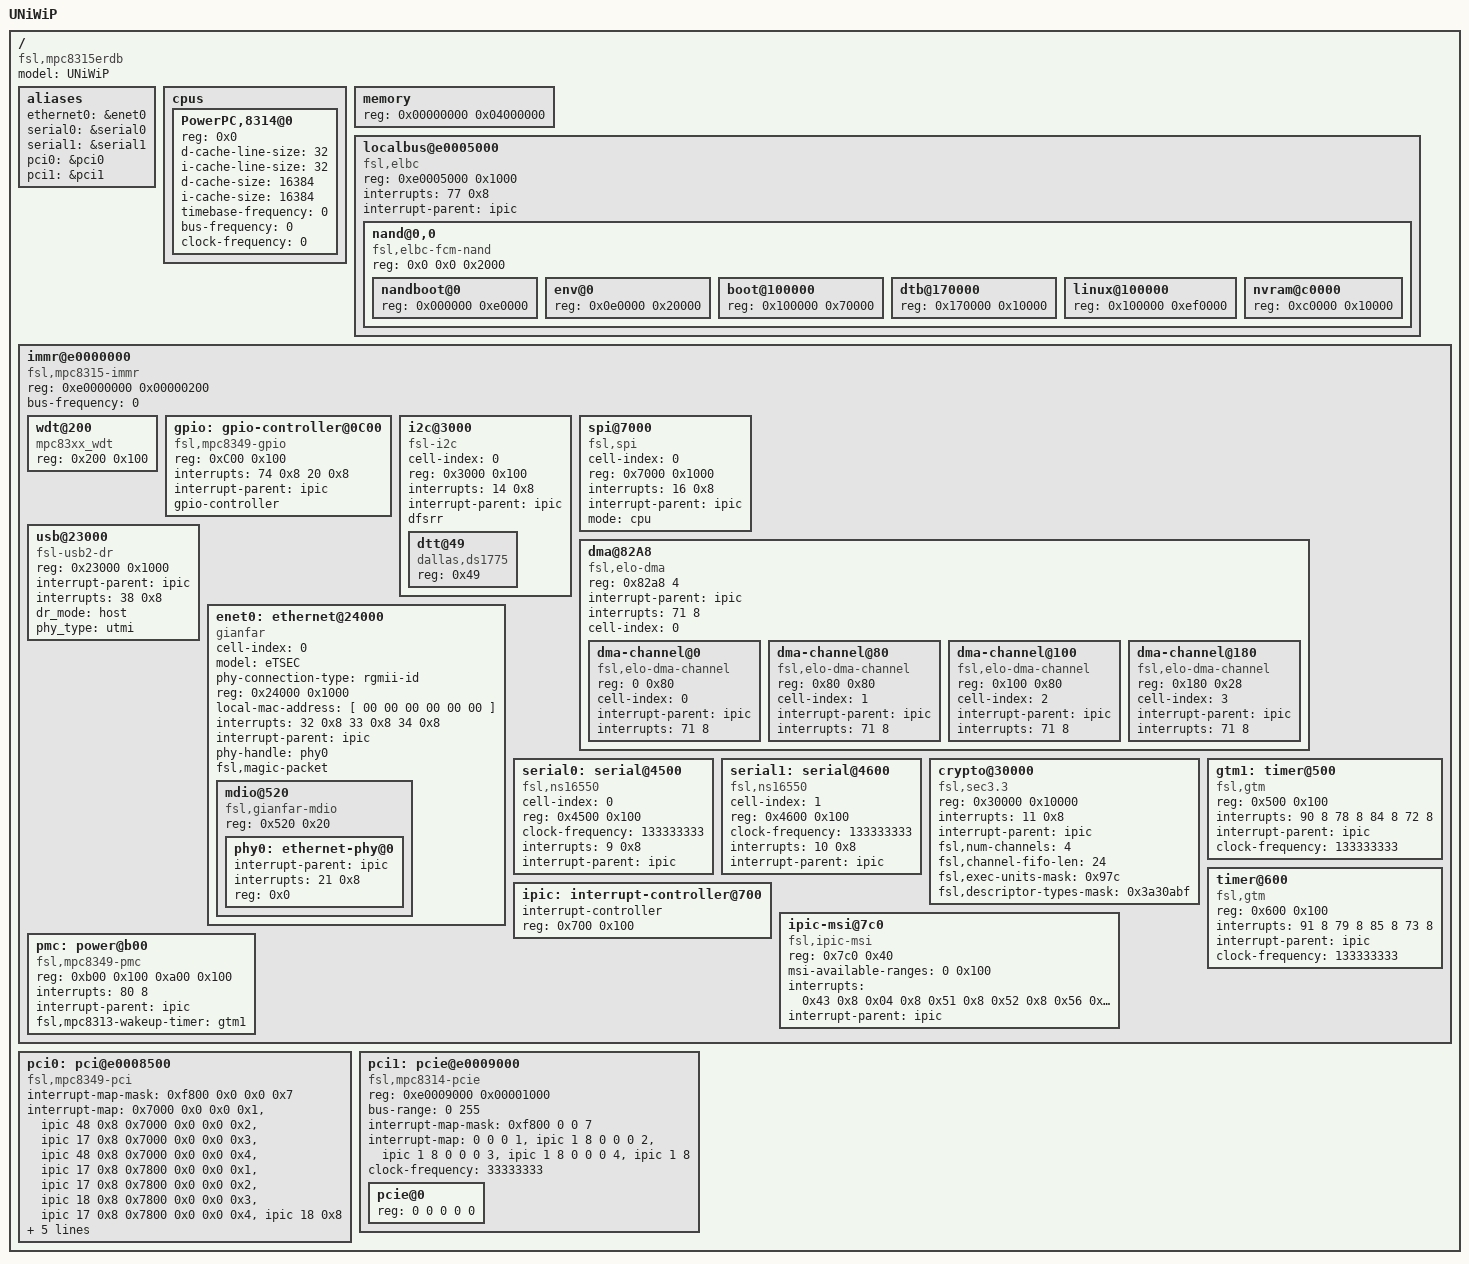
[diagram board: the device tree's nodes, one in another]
/*
 * UNiWiP Device Tree Source © 2013 Octagon Systems
 *
 * Copyright 2007 Freescale Semiconductor Inc.
 *
 * This program is free software; you can redistribute  it and/or modify it
 * under  the terms of  the GNU General  Public License as published by the
 * Free Software Foundation;  either version 2 of the  License, or (at your
 * option) any later version.
 */

/dts-v1/;

/ {
	model = "UNiWiP";
	compatible = "fsl,mpc8315erdb";
	#address-cells = <1>;
	#size-cells = <1>;

	aliases {
		ethernet0 = &enet0;
		serial0 = &serial0;
		serial1 = &serial1;
		pci0 = &pci0;
		pci1 = &pci1;
	};

	cpus {
		#address-cells = <1>;
		#size-cells = <0>;

		PowerPC,8314@0 {
			device_type = "cpu";
			reg = <0x0>;
			d-cache-line-size = <32>;
			i-cache-line-size = <32>;
			d-cache-size = <16384>;
			i-cache-size = <16384>;
			timebase-frequency = <0>;	// from bootloader
			bus-frequency = <0>;		// from bootloader
			clock-frequency = <0>;		// from bootloader
		};
	};

	memory {
		device_type = "memory";
		reg = <0x00000000 0x04000000>;	// 64MB @ 0
	};

	localbus@e0005000 {
		#address-cells = <2>;
		#size-cells = <1>;
		compatible = "fsl,elbc", "simple-bus";
		reg = <0xe0005000 0x1000>;
		interrupts = <77 0x8>;
		interrupt-parent = <&ipic>;

		ranges = <0x0 0x0 0xe0600000 0x00002000>;

		nand@0,0 {
			#address-cells = <1>;
			#size-cells = <1>;
			compatible = "fsl,elbc-fcm-nand";
			reg = <0x0 0x0 0x2000>;

			nandboot@0 {
				reg = <0x000000 0xe0000>;
			};

			env@0 {
				reg = <0x0e0000 0x20000>;
			};

			boot@100000 {
				reg = <0x100000 0x70000>;
			};

			dtb@170000 {
				reg = <0x170000 0x10000>;
			};

			linux@100000 {
				reg = <0x100000 0xef0000>;
			};

			nvram@c0000 {
				reg = <0xc0000 0x10000>;
			};
		};
	};

	immr@e0000000 {
		#address-cells = <1>;
		#size-cells = <1>;
		device_type = "soc";
		compatible = "fsl,mpc8315-immr", "simple-bus";
		ranges = <0 0xe0000000 0x00100000>;
		reg = <0xe0000000 0x00000200>;
		bus-frequency = <0>;

		wdt@200 {
			device_type = "watchdog";
			compatible = "mpc83xx_wdt";
			reg = <0x200 0x100>;
		};

		gpio: gpio-controller@0C00 {
			device_type = "gpio";
			compatible = "fsl,mpc8349-gpio";
			reg = <0xC00 0x100>;
			interrupts = <74 0x8 20 0x8>;
			interrupt-parent = <&ipic>;
			gpio-controller;
		};

                i2c@3000 {
                        device_type = "i2c";
                        #address-cells = <1>;
                        #size-cells = <0>;
                        cell-index = <0>;
                        compatible = "fsl-i2c";
                        reg = <0x3000 0x100>;
                        interrupts = <14 0x8>;
                        interrupt-parent = <&ipic>;
                        dfsrr;

                        dtt@49 {
                                compatible = "dallas,ds1775";
                                reg = <0x49>;
                        };
                };

		spi@7000 {
			device_type = "spi";
			cell-index = <0>;
			compatible = "fsl,spi";
			reg = <0x7000 0x1000>;
			interrupts = <16 0x8>;
			interrupt-parent = <&ipic>;
			mode = "cpu";
		};

		dma@82A8 {
			device_type = "dma";
			#address-cells = <1>;
			#size-cells = <1>;
			compatible = "fsl,elo-dma";
			reg = <0x82a8 4>;
			ranges = <0 0x8100 0x1a8>;
			interrupt-parent = <&ipic>;
			interrupts = <71 8>;
			cell-index = <0>;
			dma-channel@0 {
				compatible = "fsl,elo-dma-channel";
				reg = <0 0x80>;
				cell-index = <0>;
				interrupt-parent = <&ipic>;
				interrupts = <71 8>;
			};
			dma-channel@80 {
				compatible = "fsl,elo-dma-channel";
				reg = <0x80 0x80>;
				cell-index = <1>;
				interrupt-parent = <&ipic>;
				interrupts = <71 8>;
			};
			dma-channel@100 {
				compatible = "fsl,elo-dma-channel";
				reg = <0x100 0x80>;
				cell-index = <2>;
				interrupt-parent = <&ipic>;
				interrupts = <71 8>;
			};
			dma-channel@180 {
				compatible = "fsl,elo-dma-channel";
				reg = <0x180 0x28>;
				cell-index = <3>;
				interrupt-parent = <&ipic>;
				interrupts = <71 8>;
			};
		};

		usb@23000 {
			device_type = "usb";
			compatible = "fsl-usb2-dr";
			reg = <0x23000 0x1000>;
			#address-cells = <1>;
			#size-cells = <1>;
			interrupt-parent = <&ipic>;
			interrupts = <38 0x8>;
			dr_mode = "host";
			phy_type = "utmi";
		};

		enet0: ethernet@24000 {
			device_type = "network";
			#address-cells = <1>;
			#size-cells = <1>;
			cell-index = <0>;
			model = "eTSEC";
			compatible = "gianfar";
			phy-connection-type = "rgmii-id";
			reg = <0x24000 0x1000>;
			ranges = <0x0 0x24000 0x1000>;
			local-mac-address = [ 00 00 00 00 00 00 ];
			interrupts = <32 0x8 33 0x8 34 0x8>;
			interrupt-parent = <&ipic>;
			phy-handle = < &phy0 >;
			fsl,magic-packet;

			mdio@520 {
				device_type = "mdio";
				#address-cells = <1>;
				#size-cells = <0>;
				compatible = "fsl,gianfar-mdio";
				reg = <0x520 0x20>;

				phy0: ethernet-phy@0 {
					device_type = "ethernet-phy";
					interrupt-parent = <&ipic>;
					interrupts = <21 0x8>;
					reg = <0x0>;
				};
			};
		};

		serial0: serial@4500 {
			device_type = "serial";
			cell-index = <0>;
			compatible = "fsl,ns16550", "ns16550";
			reg = <0x4500 0x100>;
			clock-frequency = <133333333>;
			interrupts = <9 0x8>;
			interrupt-parent = <&ipic>;
		};

		serial1: serial@4600 {
			device_type = "serial";
			cell-index = <1>;
			compatible = "fsl,ns16550", "ns16550";
			reg = <0x4600 0x100>;
			clock-frequency = <133333333>;
			interrupts = <10 0x8>;
			interrupt-parent = <&ipic>;
		};

                crypto@30000 {
                        device_type = "crypto";
                        compatible = "fsl,sec3.3", "fsl,sec3.1", "fsl,sec3.0",
                                     "fsl,sec2.4", "fsl,sec2.2", "fsl,sec2.1",
                                     "fsl,sec2.0";
                        reg = <0x30000 0x10000>;
                        interrupts = <11 0x8>;
                        interrupt-parent = <&ipic>;
                        fsl,num-channels = <4>;
                        fsl,channel-fifo-len = <24>;
                        fsl,exec-units-mask = <0x97c>;
                        fsl,descriptor-types-mask = <0x3a30abf>;
                };

		gtm1: timer@500 {
			device_type = "gtm";
			compatible = "fsl,gtm";
			reg = <0x500 0x100>;
			interrupts = <90 8 78 8 84 8 72 8>;
			interrupt-parent = <&ipic>;
			clock-frequency = <133333333>;
		};

		timer@600 {
			device_type = "timer";
			compatible = "fsl,gtm";
			reg = <0x600 0x100>;
			interrupts = <91 8 79 8 85 8 73 8>;
			interrupt-parent = <&ipic>;
			clock-frequency = <133333333>;
		};

		/* IPIC
		 * interrupts cell = <intr #, sense>
		 * sense values match linux IORESOURCE_IRQ_* defines:
		 * sense == 8: Level, low assertion
		 * sense == 2: Edge, high-to-low change
		 */
		ipic: interrupt-controller@700 {
			device_type = "ipic";
			interrupt-controller;
			#address-cells = <0>;
			#interrupt-cells = <2>;
			reg = <0x700 0x100>;
		};

		ipic-msi@7c0 {
			device_type = "msi";
			compatible = "fsl,ipic-msi";
			reg = <0x7c0 0x40>;
			msi-available-ranges = <0 0x100>;
			interrupts = <0x43 0x8
				      0x04 0x8
				      0x51 0x8
				      0x52 0x8
				      0x56 0x8
				      0x57 0x8
				      0x58 0x8
				      0x59 0x8>;
			interrupt-parent = < &ipic >;
		};

		pmc: power@b00 {
			device_type = "pmc";
			compatible = "fsl,mpc8349-pmc";
			reg = <0xb00 0x100 0xa00 0x100>;
			interrupts = <80 8>;
			interrupt-parent = <&ipic>;
			fsl,mpc8313-wakeup-timer = <&gtm1>;
		};
	};

	pci0: pci@e0008500 {
		device_type = "pci";
		interrupt-map-mask = <0xf800 0x0 0x0 0x7>;
		interrupt-map = < 0x7000 0x0 0x0 0x1 &ipic 48 0x8   /* IDSEL 0x0E -mini PCI */
				  0x7000 0x0 0x0 0x2 &ipic 17 0x8
				  0x7000 0x0 0x0 0x3 &ipic 48 0x8
				  0x7000 0x0 0x0 0x4 &ipic 17 0x8

				  0x7800 0x0 0x0 0x1 &ipic 17 0x8   /* IDSEL 0x0F -mini PCI */
				  0x7800 0x0 0x0 0x2 &ipic 18 0x8
				  0x7800 0x0 0x0 0x3 &ipic 17 0x8
				  0x7800 0x0 0x0 0x4 &ipic 18 0x8 >;

		interrupt-parent = <&ipic>;
		interrupts = <66 0x8>;
		bus-range = <0x0 0x0>;
		ranges = < 0x02000000 0 0x90000000 0x90000000 0 0x10000000
			   0x42000000 0 0x80000000 0x80000000 0 0x10000000
			   0x01000000 0 0x00000000 0xe0300000 0 0x00100000 >;
		clock-frequency = <33333333>;
		#interrupt-cells = <1>;
		#size-cells = <2>;
		#address-cells = <3>;
		reg = <0xe0008500 0x100		/* internal registers */
		       0xe0008300 0x8>;		/* config space access registers */
		compatible = "fsl,mpc8349-pci";
	};

	pci1: pcie@e0009000 {
		device_type = "pci";
		#address-cells = <3>;
		#size-cells = <2>;
		#interrupt-cells = <1>;
		compatible = "fsl,mpc8314-pcie";
		reg = <0xe0009000 0x00001000>;
		ranges = <0x02000000 0 0xa0000000 0xa0000000 0 0x10000000
			  0x01000000 0 0x00000000 0xb1000000 0 0x00800000>;
		bus-range = <0 255>;
		interrupt-map-mask = <0xf800 0 0 7>;
		interrupt-map = <0 0 0 1 &ipic 1 8
				 0 0 0 2 &ipic 1 8
				 0 0 0 3 &ipic 1 8
				 0 0 0 4 &ipic 1 8>;
		clock-frequency = <33333333>;

		pcie@0 {
			device_type = "pci";
			#address-cells = <3>;
			#size-cells = <2>;
			reg = <0 0 0 0 0>;
			ranges = <0x02000000 0 0xa0000000
				  0x02000000 0 0xa0000000
				  0 0x10000000
				  0x01000000 0 0x00000000
				  0x01000000 0 0x00000000
				  0 0x00800000>;
		};
	};
};
